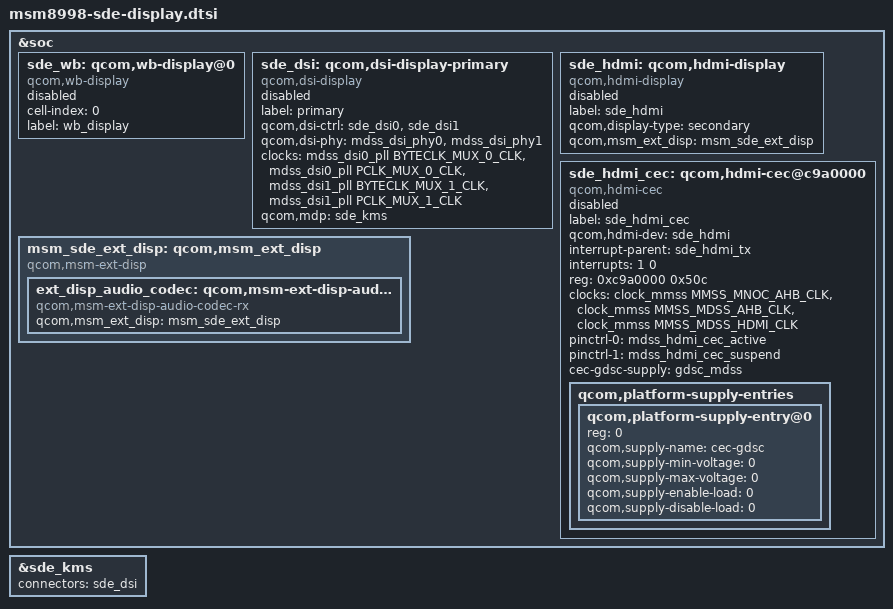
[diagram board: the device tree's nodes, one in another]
/* Copyright (c) 2017, The Linux Foundation. All rights reserved.
 *
 * This program is free software; you can redistribute it and/or modify
 * it under the terms of the GNU General Public License version 2 and
 * only version 2 as published by the Free Software Foundation.
 *
 * This program is distributed in the hope that it will be useful,
 * but WITHOUT ANY WARRANTY; without even the implied warranty of
 * MERCHANTABILITY or FITNESS FOR A PARTICULAR PURPOSE.  See the
 * GNU General Public License for more details.
 */

&soc {

	sde_wb: qcom,wb-display@0 {
		compatible = "qcom,wb-display";
		cell-index = <0>;
		label = "wb_display";
		status = "disabled";
	};

	sde_dsi: qcom,dsi-display-primary {
		compatible = "qcom,dsi-display";
		label = "primary";
		status = "disabled";

		qcom,dsi-ctrl = <&sde_dsi0 &sde_dsi1>;
		qcom,dsi-phy = <&mdss_dsi_phy0 &mdss_dsi_phy1>;

		clocks = <&mdss_dsi0_pll BYTECLK_MUX_0_CLK>,
			 <&mdss_dsi0_pll PCLK_MUX_0_CLK>,
			 <&mdss_dsi1_pll BYTECLK_MUX_1_CLK>,
			 <&mdss_dsi1_pll PCLK_MUX_1_CLK>;
		clock-names = "mux_byte_clk0", "mux_pixel_clk0",
			      "mux_byte_clk1", "mux_pixel_clk1";

		qcom,mdp = <&sde_kms>;
	};

	msm_sde_ext_disp: qcom,msm_ext_disp {
		compatible = "qcom,msm-ext-disp";

		ext_disp_audio_codec: qcom,msm-ext-disp-audio-codec-rx {
			compatible = "qcom,msm-ext-disp-audio-codec-rx";
			qcom,msm_ext_disp = <&msm_sde_ext_disp>;
		};
	};

	sde_hdmi: qcom,hdmi-display {
		compatible = "qcom,hdmi-display";
		label = "sde_hdmi";
		qcom,display-type = "secondary";
		qcom,msm_ext_disp = <&msm_sde_ext_disp>;
		status = "disabled";
	};

	sde_hdmi_cec: qcom,hdmi-cec@c9a0000 {
		compatible = "qcom,hdmi-cec";
		label = "sde_hdmi_cec";
		status = "disabled";
		qcom,hdmi-dev = <&sde_hdmi>;
		interrupt-parent = <&sde_hdmi_tx>;
		interrupts = <1 0>;

		reg = <0xc9a0000 0x50c>;
		reg-names = "hdmi_cec";

		clocks = <&clock_mmss MMSS_MNOC_AHB_CLK>,
		       <&clock_mmss MMSS_MDSS_AHB_CLK>,
		       <&clock_mmss MMSS_MDSS_HDMI_CLK>;
		clock-names = "cec_mnoc_clk", "cec_iface_clk", "cec_core_clk";

		pinctrl-names = "cec_active", "cec_sleep";
		pinctrl-0 = <&mdss_hdmi_cec_active>;
		pinctrl-1 = <&mdss_hdmi_cec_suspend>;

		cec-gdsc-supply = <&gdsc_mdss>;
		qcom,platform-supply-entries {
			#address-cells = <1>;
			#size-cells = <0>;

			qcom,platform-supply-entry@0 {
				reg = <0>;
				qcom,supply-name = "cec-gdsc";
				qcom,supply-min-voltage = <0>;
				qcom,supply-max-voltage = <0>;
				qcom,supply-enable-load = <0>;
				qcom,supply-disable-load = <0>;
			};
		};
	};
};

&sde_kms {
	connectors = <&sde_dsi>;
};
